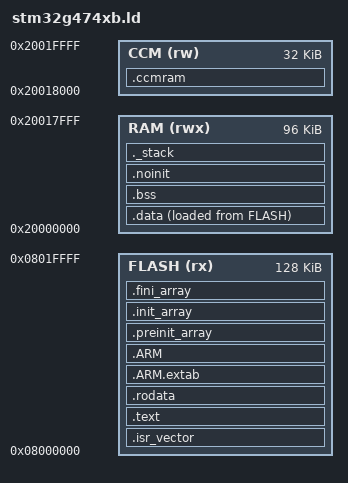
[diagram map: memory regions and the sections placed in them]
/* STM32G474xB, the smallest G474: 128 KB flash, SRAM1+SRAM2 contiguous, then CCM SRAM. */
ENTRY(Reset_Handler)

MEMORY
{
  FLASH (rx)  : ORIGIN = 0x08000000, LENGTH = 128K
  RAM   (rwx) : ORIGIN = 0x20000000, LENGTH = 96K
  CCM   (rw)  : ORIGIN = 0x20018000, LENGTH = 32K  /* CCM SRAM alias, reachable by DMA */
}

_estack = ORIGIN(RAM) + LENGTH(RAM);
_min_stack = 0x1000;

SECTIONS
{
  .isr_vector :
  {
    . = ALIGN(4);
    KEEP(*(.isr_vector))
    KEEP(*(.app_desc))
  } >FLASH

  .text :
  {
    . = ALIGN(4);
    *(.text*)
    *(.glue_7) *(.glue_7t) *(.eh_frame)
    KEEP(*(.init))
    KEEP(*(.fini))
  } >FLASH

  .rodata : { . = ALIGN(4); *(.rodata*) } >FLASH
  .ARM.extab : { *(.ARM.extab* .gnu.linkonce.armextab.*) } >FLASH
  .ARM : { __exidx_start = .; *(.ARM.exidx*) __exidx_end = .; } >FLASH

  .preinit_array :
  {
    PROVIDE_HIDDEN(__preinit_array_start = .);
    KEEP(*(.preinit_array*))
    PROVIDE_HIDDEN(__preinit_array_end = .);
  } >FLASH
  .init_array :
  {
    PROVIDE_HIDDEN(__init_array_start = .);
    KEEP(*(SORT(.init_array.*)))
    KEEP(*(.init_array*))
    PROVIDE_HIDDEN(__init_array_end = .);
  } >FLASH
  .fini_array :
  {
    PROVIDE_HIDDEN(__fini_array_start = .);
    KEEP(*(SORT(.fini_array.*)))
    KEEP(*(.fini_array*))
    PROVIDE_HIDDEN(__fini_array_end = .);
  } >FLASH

  _sidata = LOADADDR(.data);
  .data :
  {
    . = ALIGN(4);
    _sdata = .;
    *(.data*)
    . = ALIGN(4);
    _edata = .;
  } >RAM AT> FLASH

  .bss (NOLOAD) :
  {
    . = ALIGN(4);
    _sbss = .;
    __bss_start__ = _sbss;
    *(.bss*)
    *(COMMON)
    . = ALIGN(4);
    _ebss = .;
    __bss_end__ = _ebss;
  } >RAM

  .ccmram (NOLOAD) : { *(.ccmram*) } >CCM

  /* Survives a reset. */
  .noinit (NOLOAD) : { . = ALIGN(4); *(.noinit*) } >RAM

  /* Fails the link if the stack can't get at least _min_stack. */
  ._stack (NOLOAD) :
  {
    . = ALIGN(8);
    PROVIDE(end = .);
    PROVIDE(_end = .);
    . = . + _min_stack;
  } >RAM

  .ARM.attributes 0 : { *(.ARM.attributes) }
}
